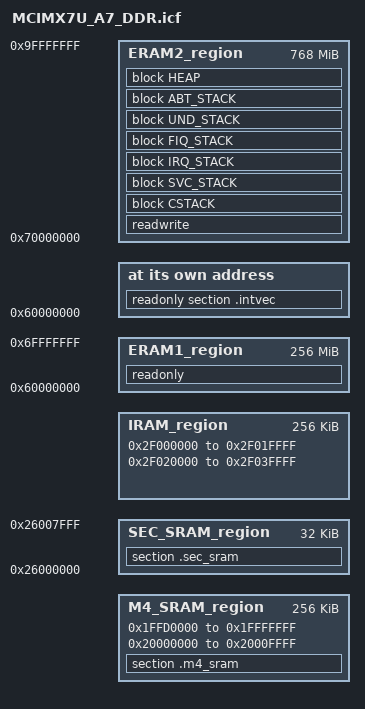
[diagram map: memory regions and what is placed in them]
/*###ICF### Section handled by ICF editor, don't touch! ****/
/*-Editor annotation file-*/
/* IcfEditorFile="$TOOLKIT_DIR$\config\ide\IcfEditor\a_v1_1.xml" */
/*-Specials-*/
define symbol __ICFEDIT_intvec_start__ = 0x60000000;
/*-Memory Regions-*/
define symbol __ICFEDIT_region_IROM1_start__ = 0x0;
define symbol __ICFEDIT_region_IROM1_end__   = 0x0;
define symbol __ICFEDIT_region_IROM2_start__ = 0x0;
define symbol __ICFEDIT_region_IROM2_end__   = 0x0;
define symbol __ICFEDIT_region_EROM1_start__ = 0x0;
define symbol __ICFEDIT_region_EROM1_end__   = 0x0;
define symbol __ICFEDIT_region_EROM2_start__ = 0x0;
define symbol __ICFEDIT_region_EROM2_end__   = 0x0;
define symbol __ICFEDIT_region_EROM3_start__ = 0x0;
define symbol __ICFEDIT_region_EROM3_end__   = 0x0;
define symbol __ICFEDIT_region_IRAM1_start__ = 0x2F000000;
define symbol __ICFEDIT_region_IRAM1_end__   = 0x2F01FFFF;
define symbol __ICFEDIT_region_IRAM2_start__ = 0x2F020000;
define symbol __ICFEDIT_region_IRAM2_end__   = 0x2F03FFFF;
define symbol __ICFEDIT_region_ERAM1_start__ = 0x60000000;
define symbol __ICFEDIT_region_ERAM1_end__   = 0x6FFFFFFF;
define symbol __ICFEDIT_region_ERAM2_start__ = 0x70000000;
define symbol __ICFEDIT_region_ERAM2_end__   = 0x9FFFFFFF;
define symbol __ICFEDIT_region_ERAM3_start__ = 0x0;
define symbol __ICFEDIT_region_ERAM3_end__   = 0x0;
/*-Sizes-*/
define symbol __ICFEDIT_size_cstack__   = 0x2000;
define symbol __ICFEDIT_size_svcstack__ = 0x100;
define symbol __ICFEDIT_size_irqstack__ = 0x100;
define symbol __ICFEDIT_size_fiqstack__ = 0x100;
define symbol __ICFEDIT_size_undstack__ = 0x100;
define symbol __ICFEDIT_size_abtstack__ = 0x100;
define symbol __ICFEDIT_size_heap__     = 0x8000;
/**** End of ICF editor section. ###ICF###*/

/* M4 SRAM_L */
define symbol M4_SRAML_start__   = 0x1FFD0000;
define symbol M4_SRAML_end__     = 0x1FFFFFFF;

/* M4 SRAM_U */
define symbol M4_SRAMU_start__   = 0x20000000;
define symbol M4_SRAMU_end__     = 0x2000FFFF;

/* 32K Secure SRAM */
define symbol SEC_SRAM_start__   = 0x26000000;
define symbol SEC_SRAM_end__     = 0x26007FFF;

define memory mem with size = 4G;
define region IROM_region     =   mem:[from __ICFEDIT_region_IROM1_start__ to __ICFEDIT_region_IROM1_end__]
                                | mem:[from __ICFEDIT_region_IROM2_start__ to __ICFEDIT_region_IROM2_end__];
define region EROM_region     =   mem:[from __ICFEDIT_region_EROM1_start__ to __ICFEDIT_region_EROM1_end__]
                                | mem:[from __ICFEDIT_region_EROM2_start__ to __ICFEDIT_region_EROM2_end__]
                                | mem:[from __ICFEDIT_region_EROM3_start__ to __ICFEDIT_region_EROM3_end__];
define region IRAM_region     =   mem:[from __ICFEDIT_region_IRAM1_start__ to __ICFEDIT_region_IRAM1_end__]
                                | mem:[from __ICFEDIT_region_IRAM2_start__ to __ICFEDIT_region_IRAM2_end__];
define region ERAM1_region    =   mem:[from __ICFEDIT_region_ERAM1_start__ to __ICFEDIT_region_ERAM1_end__];
define region ERAM2_region    =   mem:[from __ICFEDIT_region_ERAM2_start__ to __ICFEDIT_region_ERAM2_end__]
                                | mem:[from __ICFEDIT_region_ERAM3_start__ to __ICFEDIT_region_ERAM3_end__];

define region M4_SRAM_region  =   mem:[from M4_SRAML_start__ to M4_SRAML_end__]
                                | mem:[from M4_SRAMU_start__ to M4_SRAMU_end__];
define region SEC_SRAM_region =   mem:[from SEC_SRAM_start__ to SEC_SRAM_end__];

define block CSTACK    with alignment = 8, size = __ICFEDIT_size_cstack__   { };
define block SVC_STACK with alignment = 8, size = __ICFEDIT_size_svcstack__ { };
define block IRQ_STACK with alignment = 8, size = __ICFEDIT_size_irqstack__ { };
define block FIQ_STACK with alignment = 8, size = __ICFEDIT_size_fiqstack__ { };
define block UND_STACK with alignment = 8, size = __ICFEDIT_size_undstack__ { };
define block ABT_STACK with alignment = 8, size = __ICFEDIT_size_abtstack__ { };
define block HEAP      with alignment = 8, size = __ICFEDIT_size_heap__     { };

do not initialize  { section .noinit };
initialize by copy { readwrite };
if (isdefinedsymbol(__USE_DLIB_PERTHREAD))
{
  // Required in a multi-threaded application
  initialize by copy with packing = none { section __DLIB_PERTHREAD };
}

place at address mem:__ICFEDIT_intvec_start__ { readonly section .intvec };

place in ERAM1_region  { readonly };
place in EROM_region   { readonly section application_specific_ro };
place in ERAM2_region  { readwrite,
                        block CSTACK, block SVC_STACK, block IRQ_STACK, block FIQ_STACK,
                        block UND_STACK, block ABT_STACK, block HEAP };

place in M4_SRAM_region  { section .m4_sram  };
place in SEC_SRAM_region { section .sec_sram };
